AUTOSAR XML (schema 00049)
package /ControlApp
  process design ControlDesign: executable=controld
package /ControlApp/exe
  executable controld: category=APPLICATION_LEVEL, logging-behavior=USES-LOGGING, reporting-behavior=REPORTS-EXECUTION-STATE
    root sw component prototype ct_root: application-type=Control
package /ControlApp/swc
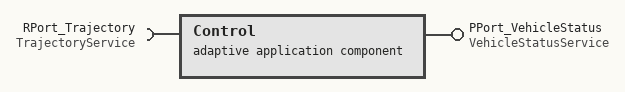
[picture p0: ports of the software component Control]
  adaptive application sw component type Control  # Trajectory tracking, unit conversion to chassis commands, rate and range limiting, staleness safe-stop, and ego speed sensing. The only process that owns the chassis link.
    require port RPort_Trajectory: required-interface=TrajectoryService  # Trajectory in. Applies steeringHorizonRad[1]; the remainder is what it follows if planning stops.
    provide port PPort_VehicleStatus: provided-interface=VehicleStatusService  # Ego speed out, decoded from the chassis. Sensed here because this is the process that holds the link.
